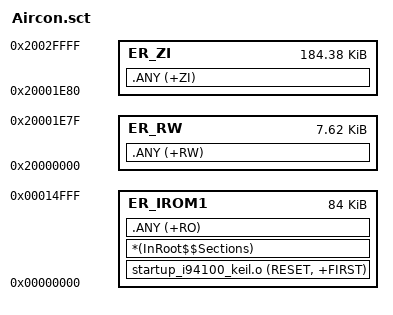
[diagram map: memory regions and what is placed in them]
LR_IROM1 0x00000000 0x00015000
{
    ER_IROM1 0x00000000 0x00015000
    {
        startup_i94100_keil.o (RESET, +FIRST)
        *(InRoot$$Sections)
        .ANY (+RO)
    }
    ER_RW 0x20000000 0x00001E80
    {
        .ANY (+RW)
    }
    ER_ZI 0x20001E80 0x0002E180
    {
        .ANY (+ZI)
    }
}
